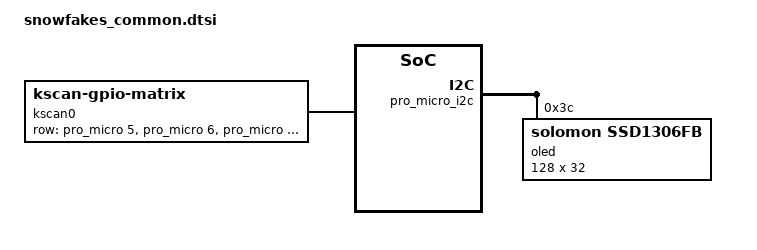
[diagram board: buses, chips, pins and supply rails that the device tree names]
// Copyright 2025 saikocat (@saikocat)
// SPDX-License-Identifier: MIT

#include <dt-bindings/zmk/matrix_transform.h>

#include "snowfakes_layout.dtsi"
#include "snowfakes_peripheral_rgbled.dtsi"

/ {
    chosen {
        zephyr,display = &oled;
        zmk,kscan = &kscan0;
        // TODO: temporarily disable due to not compat with ui editor
        // zmk,physical-layout = &snowfakes_layout;
        zmk,matrix_transform = &default_transform;
    };

    kscan0: kscan0 {
        compatible = "zmk,kscan-gpio-matrix";
        diode-direction = "col2row";
        wakeup-source;

        row-gpios
            = <&pro_micro 5 (GPIO_ACTIVE_HIGH | GPIO_PULL_DOWN)>
            , <&pro_micro 6 (GPIO_ACTIVE_HIGH | GPIO_PULL_DOWN)>
            , <&pro_micro 7 (GPIO_ACTIVE_HIGH | GPIO_PULL_DOWN)>
            , <&pro_micro 8 (GPIO_ACTIVE_HIGH | GPIO_PULL_DOWN)>
            ;
    };
};

&pro_micro_i2c {
    status = "okay";

    oled: ssd1306@3c {
        compatible = "solomon,ssd1306fb";
        reg = <0x3c>;
        width = <128>;
        height = <32>;
        segment-offset = <0>;
        page-offset = <0>;
        display-offset = <0>;
        multiplex-ratio = <31>;
        segment-remap;
        com-invdir;
        com-sequential;
        inversion-on;
        prechargep = <0x22>;
    };
};
